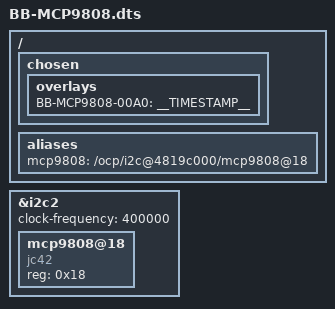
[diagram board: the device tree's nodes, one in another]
/*
 */
/dts-v1/;
/plugin/;

/ {
	/*
	 * Helper to show loaded overlays under: /proc/device-tree/chosen/overlays/
	 */
	fragment@0 {
		target-path="/";
		__overlay__ {
			chosen {
				overlays {
					BB-MCP9808-00A0 = __TIMESTAMP__;
				};
			};
		};
	};

	fragment@1 {
		target-path="/";
		__overlay__ {

			aliases {
				/* SLOT I2C2 */
				mcp9808 = "/ocp/i2c@4819c000/mcp9808@18";
			};
		};
	};

	fragment@2 {
		/* SLOT I2C2 */
		target = <&i2c2>;
		__overlay__ {
			status = "okay";

			/* this is the configuration part */
			clock-frequency = <400000>;

			#address-cells = <1>;
			#size-cells = <0>;

			mcp9808@18 {
				compatible = "jc42";
				reg = <0x18>;
				status = "okay";
			};
		};
	};
};

